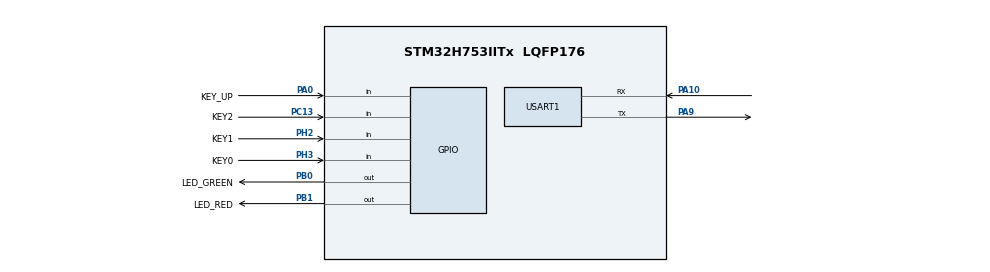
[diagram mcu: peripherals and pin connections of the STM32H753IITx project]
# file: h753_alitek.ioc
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CORTEX_M7.default_mode_Activation=1
FREERTOS.Tasks01=defaultTask,24,256,StartDefaultTask,Default,NULL,Dynamic,NULL,NULL
Mcu.Family=STM32H7
Mcu.Name=STM32H753IITx
Mcu.Package=LQFP176
NVIC.PriorityGroup=NVIC_PRIORITYGROUP_4
NVIC.TIM1_UP_IRQn=true\:15\:0\:false\:false\:true\:false\:false\:true\:true
NVIC.TimeBase=TIM1_UP_IRQn
NVIC.TimeBaseIP=TIM1
PA0.GPIO_Label=KEY_UP
PA0.GPIO_PuPd=GPIO_PULLDOWN
PA0.Signal=GPIO_Input
PA10.Mode=Asynchronous
PA10.Signal=USART1_RX
PA9.GPIO_PuPd=GPIO_PULLUP
PA9.GPIO_Speed=GPIO_SPEED_FREQ_HIGH
PA9.Mode=Asynchronous
PA9.Signal=USART1_TX
PB0.GPIO_Label=LED_GREEN
PB0.GPIO_PuPd=GPIO_PULLUP
PB0.Signal=GPIO_Output
PB1.GPIO_Label=LED_RED
PB1.GPIO_PuPd=GPIO_PULLUP
PB1.Signal=GPIO_Output
PC13.GPIO_Label=KEY2
PC13.GPIO_PuPd=GPIO_PULLUP
PC13.Signal=GPIO_Input
PH2.GPIO_Label=KEY1
PH2.GPIO_PuPd=GPIO_PULLUP
PH2.Signal=GPIO_Input
PH3.GPIO_Label=KEY0
PH3.GPIO_PuPd=GPIO_PULLUP
PH3.Signal=GPIO_Input
ProjectManager.HeapSize=0x200
ProjectManager.StackSize=0x400
ProjectManager.TargetToolchain=CMake
RCC.ADCFreq_Value=129000000
RCC.APB1Freq_Value=64000000
RCC.APB2Freq_Value=32000000
RCC.APB3Freq_Value=64000000
RCC.APB4Freq_Value=64000000
RCC.CortexFreq_Value=128000000
RCC.D1PPRE=RCC_APB3_DIV2
RCC.D2PPRE1=RCC_APB1_DIV2
RCC.D2PPRE2=RCC_APB2_DIV4
RCC.D3PPRE=RCC_APB4_DIV2
RCC.DIVM1=4
RCC.DIVN1=16
RCC.HCLKFreq_Value=128000000
RCC.PLL2FRACN=0
RCC.PLL3FRACN=0
RCC.PLLFRACN=0
RCC.SYSCLKFreq_VALUE=128000000
RCC.SYSCLKSource=RCC_SYSCLKSOURCE_PLLCLK
RCC.USBFreq_Value=128000000
USART1.VirtualMode-Asynchronous=VM_ASYNC
VP_FREERTOS_VS_CMSIS_V2.Mode=CMSIS_V2
VP_MEMORYMAP_VS_MEMORYMAP.Mode=CurAppReg
VP_SYS_VS_tim1.Mode=TIM1
board=custom

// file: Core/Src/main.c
/* USER CODE BEGIN Header */
/**
  ******************************************************************************
  * @file           : main.c
  * @brief          : Main program body
  ******************************************************************************
  * @attention
  *
  * Copyright (c) 2025 STMicroelectronics.
  * All rights reserved.
  *
  * This software is licensed under terms that can be found in the LICENSE file
  * in the root directory of this software component.
  * If no LICENSE file comes with this software, it is provided AS-IS.
  *
  ******************************************************************************
  */
/* USER CODE END Header */
#include "main.h"
#include "cmsis_os.h"

/* USER CODE BEGIN Includes */
#include "log.h"
/* USER CODE END Includes */

UART_HandleTypeDef huart1;

/* Definitions for defaultTask */
osThreadId_t defaultTaskHandle;
const osThreadAttr_t defaultTask_attributes = {
  .name = "defaultTask",
  .stack_size = 256 * 4,
  .priority = (osPriority_t) osPriorityNormal,
};

void SystemClock_Config(void);
static void MPU_Config(void);
static void MX_GPIO_Init(void);
static void MX_USART1_UART_Init(void);
void StartDefaultTask(void *argument);

int main(void)
{

  /* MPU Configuration--------------------------------------------------------*/
  MPU_Config();

  /* MCU Configuration--------------------------------------------------------*/

  /* Reset of all peripherals, Initializes the Flash interface and the Systick. */
  HAL_Init();

  /* Configure the system clock */
  SystemClock_Config();

  /* Initialize all configured peripherals */
  MX_GPIO_Init();
  MX_USART1_UART_Init();

  /* Init scheduler */
  osKernelInitialize();

  /* Create the thread(s) */
  /* creation of defaultTask */
  defaultTaskHandle = osThreadNew(StartDefaultTask, NULL, &defaultTask_attributes);

  /* Start scheduler */
  osKernelStart();

  /* We should never get here as control is now taken by the scheduler */

  /* Infinite loop */
  while (1)
  {

  }
}

void SystemClock_Config(void)
{
  RCC_OscInitTypeDef RCC_OscInitStruct = {0};
  RCC_ClkInitTypeDef RCC_ClkInitStruct = {0};

  /** Supply configuration update enable
  */
  HAL_PWREx_ConfigSupply(PWR_LDO_SUPPLY);

  /** Configure the main internal regulator output voltage
  */
  __HAL_PWR_VOLTAGESCALING_CONFIG(PWR_REGULATOR_VOLTAGE_SCALE3);

  while(!__HAL_PWR_GET_FLAG(PWR_FLAG_VOSRDY)) {}

  /** Initializes the RCC Oscillators according to the specified parameters
  * in the RCC_OscInitTypeDef structure.
  */
  RCC_OscInitStruct.OscillatorType = RCC_OSCILLATORTYPE_HSI;
  RCC_OscInitStruct.HSIState = RCC_HSI_DIV1;
  RCC_OscInitStruct.HSICalibrationValue = RCC_HSICALIBRATION_DEFAULT;
  RCC_OscInitStruct.PLL.PLLState = RCC_PLL_ON;
  RCC_OscInitStruct.PLL.PLLSource = RCC_PLLSOURCE_HSI;
  RCC_OscInitStruct.PLL.PLLM = 4;
  RCC_OscInitStruct.PLL.PLLN = 16;
  RCC_OscInitStruct.PLL.PLLP = 2;
  RCC_OscInitStruct.PLL.PLLQ = 2;
  RCC_OscInitStruct.PLL.PLLR = 2;
  RCC_OscInitStruct.PLL.PLLRGE = RCC_PLL1VCIRANGE_3;
  RCC_OscInitStruct.PLL.PLLVCOSEL = RCC_PLL1VCOWIDE;
  RCC_OscInitStruct.PLL.PLLFRACN = 0;
  if (HAL_RCC_OscConfig(&RCC_OscInitStruct) != HAL_OK)
  {
    Error_Handler();
  }

  /** Initializes the CPU, AHB and APB buses clocks
  */
  RCC_ClkInitStruct.ClockType = RCC_CLOCKTYPE_HCLK|RCC_CLOCKTYPE_SYSCLK
                              |RCC_CLOCKTYPE_PCLK1|RCC_CLOCKTYPE_PCLK2
                              |RCC_CLOCKTYPE_D3PCLK1|RCC_CLOCKTYPE_D1PCLK1;
  RCC_ClkInitStruct.SYSCLKSource = RCC_SYSCLKSOURCE_PLLCLK;
  RCC_ClkInitStruct.SYSCLKDivider = RCC_SYSCLK_DIV1;
  RCC_ClkInitStruct.AHBCLKDivider = RCC_HCLK_DIV1;
  RCC_ClkInitStruct.APB3CLKDivider = RCC_APB3_DIV2;
  RCC_ClkInitStruct.APB1CLKDivider = RCC_APB1_DIV2;
  RCC_ClkInitStruct.APB2CLKDivider = RCC_APB2_DIV4;
  RCC_ClkInitStruct.APB4CLKDivider = RCC_APB4_DIV2;

  if (HAL_RCC_ClockConfig(&RCC_ClkInitStruct, FLASH_LATENCY_2) != HAL_OK)
  {
    Error_Handler();
  }
}

static void MX_USART1_UART_Init(void)
{

  huart1.Instance = USART1;
  huart1.Init.BaudRate = 115200;
  huart1.Init.WordLength = UART_WORDLENGTH_8B;
  huart1.Init.StopBits = UART_STOPBITS_1;
  huart1.Init.Parity = UART_PARITY_NONE;
  huart1.Init.Mode = UART_MODE_TX_RX;
  huart1.Init.HwFlowCtl = UART_HWCONTROL_NONE;
  huart1.Init.OverSampling = UART_OVERSAMPLING_16;
  huart1.Init.OneBitSampling = UART_ONE_BIT_SAMPLE_DISABLE;
  huart1.Init.ClockPrescaler = UART_PRESCALER_DIV1;
  huart1.AdvancedInit.AdvFeatureInit = UART_ADVFEATURE_NO_INIT;
  if (HAL_UART_Init(&huart1) != HAL_OK)
  {
    Error_Handler();
  }
  if (HAL_UARTEx_SetTxFifoThreshold(&huart1, UART_TXFIFO_THRESHOLD_1_8) != HAL_OK)
  {
    Error_Handler();
  }
  if (HAL_UARTEx_SetRxFifoThreshold(&huart1, UART_RXFIFO_THRESHOLD_1_8) != HAL_OK)
  {
    Error_Handler();
  }
  if (HAL_UARTEx_DisableFifoMode(&huart1) != HAL_OK)
  {
    Error_Handler();
  }

}

static void MX_GPIO_Init(void)
{
  GPIO_InitTypeDef GPIO_InitStruct = {0};

  /* GPIO Ports Clock Enable */
  __HAL_RCC_GPIOC_CLK_ENABLE();
  __HAL_RCC_GPIOA_CLK_ENABLE();
  __HAL_RCC_GPIOH_CLK_ENABLE();
  __HAL_RCC_GPIOB_CLK_ENABLE();

  /*Configure GPIO pin Output Level */
  HAL_GPIO_WritePin(GPIOB, LED_GREEN_Pin|LED_RED_Pin, GPIO_PIN_RESET);

  /*Configure GPIO pin : KEY2_Pin */
  GPIO_InitStruct.Pin = KEY2_Pin;
  GPIO_InitStruct.Mode = GPIO_MODE_INPUT;
  GPIO_InitStruct.Pull = GPIO_PULLUP;
  HAL_GPIO_Init(KEY2_GPIO_Port, &GPIO_InitStruct);

  /*Configure GPIO pin : KEY_UP_Pin */
  GPIO_InitStruct.Pin = KEY_UP_Pin;
  GPIO_InitStruct.Mode = GPIO_MODE_INPUT;
  GPIO_InitStruct.Pull = GPIO_PULLDOWN;
  HAL_GPIO_Init(KEY_UP_GPIO_Port, &GPIO_InitStruct);

  /*Configure GPIO pins : KEY1_Pin KEY0_Pin */
  GPIO_InitStruct.Pin = KEY1_Pin|KEY0_Pin;
  GPIO_InitStruct.Mode = GPIO_MODE_INPUT;
  GPIO_InitStruct.Pull = GPIO_PULLUP;
  HAL_GPIO_Init(GPIOH, &GPIO_InitStruct);

  /*Configure GPIO pins : LED_GREEN_Pin LED_RED_Pin */
  GPIO_InitStruct.Pin = LED_GREEN_Pin|LED_RED_Pin;
  GPIO_InitStruct.Mode = GPIO_MODE_OUTPUT_PP;
  GPIO_InitStruct.Pull = GPIO_PULLUP;
  GPIO_InitStruct.Speed = GPIO_SPEED_FREQ_LOW;
  HAL_GPIO_Init(GPIOB, &GPIO_InitStruct);

}

void StartDefaultTask(void *argument)
{
  /* USER CODE BEGIN 5 */
  log_init(); // Initialize the logging system
  /* Infinite loop */
  for(;;)
  {
    osDelay(1000);
    HAL_GPIO_TogglePin(GPIOB, GPIO_PIN_0); // Toggle LED on PB0
    HAL_GPIO_TogglePin(GPIOB, GPIO_PIN_1); // Toggle LED on PB
    loge("log test");
  }
  /* USER CODE END 5 */
}

 /* MPU Configuration */

void MPU_Config(void)
{
  MPU_Region_InitTypeDef MPU_InitStruct = {0};

  /* Disables the MPU */
  HAL_MPU_Disable();

  /** Initializes and configures the Region and the memory to be protected
  */
  MPU_InitStruct.Enable = MPU_REGION_ENABLE;
  MPU_InitStruct.Number = MPU_REGION_NUMBER0;
  MPU_InitStruct.BaseAddress = 0x0;
  MPU_InitStruct.Size = MPU_REGION_SIZE_4GB;
  MPU_InitStruct.SubRegionDisable = 0x87;
  MPU_InitStruct.TypeExtField = MPU_TEX_LEVEL0;
  MPU_InitStruct.AccessPermission = MPU_REGION_NO_ACCESS;
  MPU_InitStruct.DisableExec = MPU_INSTRUCTION_ACCESS_DISABLE;
  MPU_InitStruct.IsShareable = MPU_ACCESS_SHAREABLE;
  MPU_InitStruct.IsCacheable = MPU_ACCESS_NOT_CACHEABLE;
  MPU_InitStruct.IsBufferable = MPU_ACCESS_NOT_BUFFERABLE;

  HAL_MPU_ConfigRegion(&MPU_InitStruct);
  /* Enables the MPU */
  HAL_MPU_Enable(MPU_PRIVILEGED_DEFAULT);

}

void HAL_TIM_PeriodElapsedCallback(TIM_HandleTypeDef *htim)
{
  if (htim->Instance == TIM1)
  {
    HAL_IncTick();
  }
}

void Error_Handler(void)
{
  __disable_irq();
  while (1)
  {
  }
}
